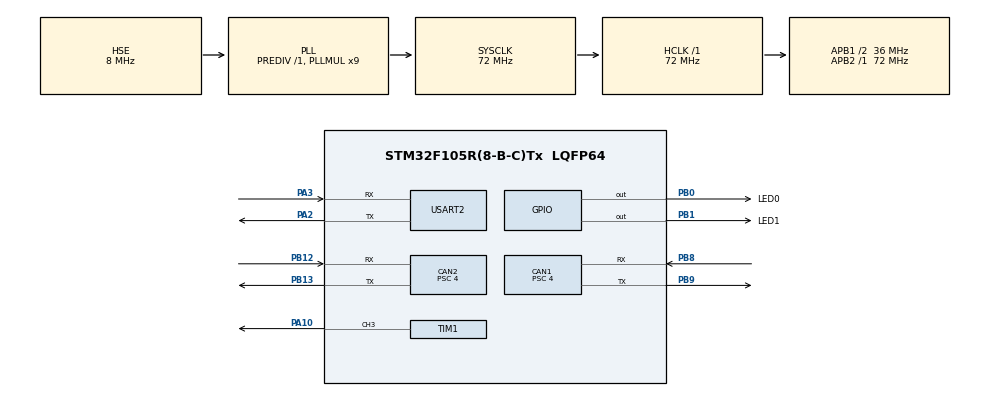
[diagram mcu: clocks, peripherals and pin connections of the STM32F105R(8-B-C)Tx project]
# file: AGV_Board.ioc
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CAN1.ABOM=ENABLE
CAN1.BS1=CAN_BS1_5TQ
CAN1.BS2=CAN_BS2_3TQ
CAN1.CalculateBaudRate=1000000
CAN1.CalculateTimeBit=1000
CAN1.CalculateTimeQuantum=111.11111111111111
CAN1.Mode=CAN_MODE_NORMAL
CAN1.Prescaler=4
CAN2.ABOM=ENABLE
CAN2.AWUM=ENABLE
CAN2.BS1=CAN_BS1_3TQ
CAN2.BS2=CAN_BS2_5TQ
CAN2.CalculateBaudRate=1000000
CAN2.CalculateTimeBit=1000
CAN2.CalculateTimeQuantum=111.11111111111111
CAN2.Prescaler=4
Dma.Request0=USART2_RX
Dma.Request1=USART2_TX
Dma.USART2_RX.0.Direction=DMA_PERIPH_TO_MEMORY
Dma.USART2_RX.0.Instance=DMA1_Channel6
Dma.USART2_RX.0.MemDataAlignment=DMA_MDATAALIGN_BYTE
Dma.USART2_RX.0.MemInc=DMA_MINC_ENABLE
Dma.USART2_RX.0.Mode=DMA_NORMAL
Dma.USART2_RX.0.PeriphDataAlignment=DMA_PDATAALIGN_BYTE
Dma.USART2_RX.0.PeriphInc=DMA_PINC_DISABLE
Dma.USART2_RX.0.Priority=DMA_PRIORITY_HIGH
Dma.USART2_TX.1.Direction=DMA_MEMORY_TO_PERIPH
Dma.USART2_TX.1.Instance=DMA1_Channel7
Dma.USART2_TX.1.MemDataAlignment=DMA_MDATAALIGN_BYTE
Dma.USART2_TX.1.MemInc=DMA_MINC_ENABLE
Dma.USART2_TX.1.Mode=DMA_NORMAL
Dma.USART2_TX.1.PeriphDataAlignment=DMA_PDATAALIGN_BYTE
Dma.USART2_TX.1.PeriphInc=DMA_PINC_DISABLE
Dma.USART2_TX.1.Priority=DMA_PRIORITY_HIGH
FREERTOS.Tasks01=defaultTask,24,128,StartDefaultTask,Default,NULL,Dynamic,NULL,NULL;steering_wheel_task,40,800,Steering_Wheel_Task,As external,NULL,Dynamic,NULL,NULL
FREERTOS.configGENERATE_RUN_TIME_STATS=1
FREERTOS.configMAX_TASK_NAME_LEN=50
FREERTOS.configUSE_STATS_FORMATTING_FUNCTIONS=1
Mcu.Family=STM32F1
Mcu.Name=STM32F105R(8-B-C)Tx
Mcu.Package=LQFP64
NVIC.CAN1_RX0_IRQn=true\:5\:0\:false\:false\:true\:true\:true\:true\:true
NVIC.CAN1_RX1_IRQn=true\:5\:0\:false\:false\:true\:true\:true\:true\:true
NVIC.CAN2_RX0_IRQn=true\:5\:0\:false\:false\:true\:true\:true\:true\:true
NVIC.CAN2_RX1_IRQn=true\:5\:0\:false\:false\:true\:true\:true\:true\:true
NVIC.DMA1_Channel6_IRQn=true\:5\:0\:false\:false\:true\:true\:false\:true\:true
NVIC.DMA1_Channel7_IRQn=true\:5\:0\:false\:false\:true\:true\:false\:true\:true
NVIC.PriorityGroup=NVIC_PRIORITYGROUP_4
NVIC.TIM7_IRQn=true\:15\:0\:false\:false\:true\:false\:false\:true\:true
NVIC.TimeBase=TIM7_IRQn
NVIC.TimeBaseIP=TIM7
PA10.Signal=S_TIM1_CH3
PA13.Mode=Serial_Wire
PA13.Signal=SYS_JTMS-SWDIO
PA14.Mode=Serial_Wire
PA14.Signal=SYS_JTCK-SWCLK
PA2.Mode=Asynchronous
PA2.Signal=USART2_TX
PA3.GPIO_PuPd=GPIO_NOPULL
PA3.Mode=Asynchronous
PA3.Signal=USART2_RX
PB0.GPIO_Label=LED0
PB0.GPIO_PuPd=GPIO_PULLDOWN
PB0.PinState=GPIO_PIN_RESET
PB0.Signal=GPIO_Output
PB1.GPIO_Label=LED1
PB1.GPIO_PuPd=GPIO_PULLDOWN
PB1.PinState=GPIO_PIN_RESET
PB1.Signal=GPIO_Output
PB12.Mode=CAN_Activate
PB12.Signal=CAN2_RX
PB13.Mode=CAN_Activate
PB13.Signal=CAN2_TX
PB8.Mode=CAN_Activate
PB8.Signal=CAN1_RX
PB9.Mode=CAN_Activate
PB9.Signal=CAN1_TX
PD0-OSC_IN.Mode=HSE-External-Oscillator
PD0-OSC_IN.Signal=RCC_OSC_IN
PD1-OSC_OUT.Mode=HSE-External-Oscillator
PD1-OSC_OUT.Signal=RCC_OSC_OUT
ProjectManager.HeapSize=0x200
ProjectManager.StackSize=0x400
ProjectManager.TargetToolchain=MDK-ARM V5.32
RCC.AHBFreq_Value=72000000
RCC.APB1CLKDivider=RCC_HCLK_DIV2
RCC.APB1Freq_Value=36000000
RCC.APB1TimFreq_Value=72000000
RCC.APB2Freq_Value=72000000
RCC.APB2TimFreq_Value=72000000
RCC.HCLKFreq_Value=72000000
RCC.PLLMUL=RCC_PLL_MUL9
RCC.PLLSourceVirtual=RCC_PLLSOURCE_HSE
RCC.SYSCLKFreq_VALUE=72000000
RCC.SYSCLKSource=RCC_SYSCLKSOURCE_PLLCLK
RCC.USBFreq_Value=48000000
SH.S_TIM1_CH3.0=TIM1_CH3,PWM Generation3 CH3
TIM1.AutoReloadPreload=TIM_AUTORELOAD_PRELOAD_ENABLE
TIM1.Channel-PWM\ Generation3\ CH3=TIM_CHANNEL_3
TIM1.Period=1000-1
TIM1.Prescaler=36
USART2.VirtualMode=VM_ASYNC
VP_FREERTOS_VS_CMSIS_V2.Mode=CMSIS_V2
VP_SYS_VS_tim7.Mode=TIM7
board=custom

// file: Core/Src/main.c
/* USER CODE BEGIN Header */
/**
  ******************************************************************************
  * @file           : main.c
  * @brief          : Main program body
  ******************************************************************************
  * @attention
  *
  * Copyright (c) 2024 STMicroelectronics.
  * All rights reserved.
  *
  * This software is licensed under terms that can be found in the LICENSE file
  * in the root directory of this software component.
  * If no LICENSE file comes with this software, it is provided AS-IS.
  *
  ******************************************************************************
  */
/* USER CODE END Header */
#include "main.h"
#include "cmsis_os.h"
#include "can.h"
#include "dma.h"
#include "tim.h"
#include "usart.h"
#include "gpio.h"

/* USER CODE BEGIN Includes */
#include "tsk_config_and_callback.h"

/* USER CODE END Includes */

void SystemClock_Config(void);
void MX_FREERTOS_Init(void);

int main(void)
{

  /* MCU Configuration--------------------------------------------------------*/

  /* Reset of all peripherals, Initializes the Flash interface and the Systick. */
  HAL_Init();

  /* Configure the system clock */
  SystemClock_Config();

  /* Initialize all configured peripherals */
  MX_GPIO_Init();
  MX_DMA_Init();
  MX_CAN1_Init();
  MX_CAN2_Init();
  MX_TIM1_Init();
  MX_USART2_UART_Init();
  /* USER CODE BEGIN 2 */
Task_Init();
  /* USER CODE END 2 */

  /* Init scheduler */
  osKernelInitialize();

  /* Call init function for freertos objects (in cmsis_os2.c) */
  MX_FREERTOS_Init();

  /* Start scheduler */
  osKernelStart();

  /* We should never get here as control is now taken by the scheduler */

  /* Infinite loop */
  while (1)
  {

  }
}

void SystemClock_Config(void)
{
  RCC_OscInitTypeDef RCC_OscInitStruct = {0};
  RCC_ClkInitTypeDef RCC_ClkInitStruct = {0};

  /** Initializes the RCC Oscillators according to the specified parameters
  * in the RCC_OscInitTypeDef structure.
  */
  RCC_OscInitStruct.OscillatorType = RCC_OSCILLATORTYPE_HSE;
  RCC_OscInitStruct.HSEState = RCC_HSE_ON;
  RCC_OscInitStruct.HSEPredivValue = RCC_HSE_PREDIV_DIV1;
  RCC_OscInitStruct.HSIState = RCC_HSI_ON;
  RCC_OscInitStruct.Prediv1Source = RCC_PREDIV1_SOURCE_HSE;
  RCC_OscInitStruct.PLL.PLLState = RCC_PLL_ON;
  RCC_OscInitStruct.PLL.PLLSource = RCC_PLLSOURCE_HSE;
  RCC_OscInitStruct.PLL.PLLMUL = RCC_PLL_MUL9;
  RCC_OscInitStruct.PLL2.PLL2State = RCC_PLL_NONE;
  if (HAL_RCC_OscConfig(&RCC_OscInitStruct) != HAL_OK)
  {
    Error_Handler();
  }

  /** Initializes the CPU, AHB and APB buses clocks
  */
  RCC_ClkInitStruct.ClockType = RCC_CLOCKTYPE_HCLK|RCC_CLOCKTYPE_SYSCLK
                              |RCC_CLOCKTYPE_PCLK1|RCC_CLOCKTYPE_PCLK2;
  RCC_ClkInitStruct.SYSCLKSource = RCC_SYSCLKSOURCE_PLLCLK;
  RCC_ClkInitStruct.AHBCLKDivider = RCC_SYSCLK_DIV1;
  RCC_ClkInitStruct.APB1CLKDivider = RCC_HCLK_DIV2;
  RCC_ClkInitStruct.APB2CLKDivider = RCC_HCLK_DIV1;

  if (HAL_RCC_ClockConfig(&RCC_ClkInitStruct, FLASH_LATENCY_2) != HAL_OK)
  {
    Error_Handler();
  }

  /** Configure the Systick interrupt time
  */
  __HAL_RCC_PLLI2S_ENABLE();
}

void HAL_TIM_PeriodElapsedCallback(TIM_HandleTypeDef *htim)
{
  if (htim->Instance == TIM7) {
    HAL_IncTick();
  }
}

void Error_Handler(void)
{
  __disable_irq();
  while (1)
  {
  }
}

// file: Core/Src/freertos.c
/* USER CODE BEGIN Header */
/**
  ******************************************************************************
  * File Name          : freertos.c
  * Description        : Code for freertos applications
  ******************************************************************************
  * @attention
  *
  * Copyright (c) 2024 STMicroelectronics.
  * All rights reserved.
  *
  * This software is licensed under terms that can be found in the LICENSE file
  * in the root directory of this software component.
  * If no LICENSE file comes with this software, it is provided AS-IS.
  *
  ******************************************************************************
  */
/* USER CODE END Header */

#include "FreeRTOS.h"
#include "task.h"
#include "main.h"
#include "cmsis_os.h"

/* USER CODE BEGIN Includes */
//#include "Steering_Wheel_Task.h"
/* USER CODE END Includes */

/* Definitions for defaultTask */
osThreadId_t defaultTaskHandle;
const osThreadAttr_t defaultTask_attributes = {
  .name = "defaultTask",
  .stack_size = 128 * 4,
  .priority = (osPriority_t) osPriorityNormal,
};
/* Definitions for steering_wheel_task */
osThreadId_t steering_wheel_taskHandle;
const osThreadAttr_t steering_wheel_task_attributes = {
  .name = "steering_wheel_task",
  .stack_size = 800 * 4,
  .priority = (osPriority_t) osPriorityHigh,
};

void StartDefaultTask(void *argument);
extern void Steering_Wheel_Task(void *argument);

void MX_FREERTOS_Init(void); /* (MISRA C 2004 rule 8.1) */

/* Hook prototypes */
void configureTimerForRunTimeStats(void);
unsigned long getRunTimeCounterValue(void);

/* USER CODE BEGIN 1 */
/* Functions needed when configGENERATE_RUN_TIME_STATS is on */
__weak void configureTimerForRunTimeStats(void)
{

}

__weak unsigned long getRunTimeCounterValue(void)
{
return 0;
}
/* USER CODE END 1 */

void MX_FREERTOS_Init(void) {

  /* Create the thread(s) */
  /* creation of defaultTask */
  defaultTaskHandle = osThreadNew(StartDefaultTask, NULL, &defaultTask_attributes);

  /* creation of steering_wheel_task */
  steering_wheel_taskHandle = osThreadNew(Steering_Wheel_Task, NULL, &steering_wheel_task_attributes);

}

/* USER CODE BEGIN Header_StartDefaultTask */
int i=0;
int n=0;
/**
  * @brief  Function implementing the defaultTask thread.
  * @param  argument: Not used
  * @retval None
  */
/* USER CODE END Header_StartDefaultTask */
void StartDefaultTask(void *argument)
{
  /* USER CODE BEGIN StartDefaultTask */
  /* Infinite loop */
  for(;;)
  {
     i++;
    osDelay(1);
  }
  /* USER CODE END StartDefaultTask */
}
